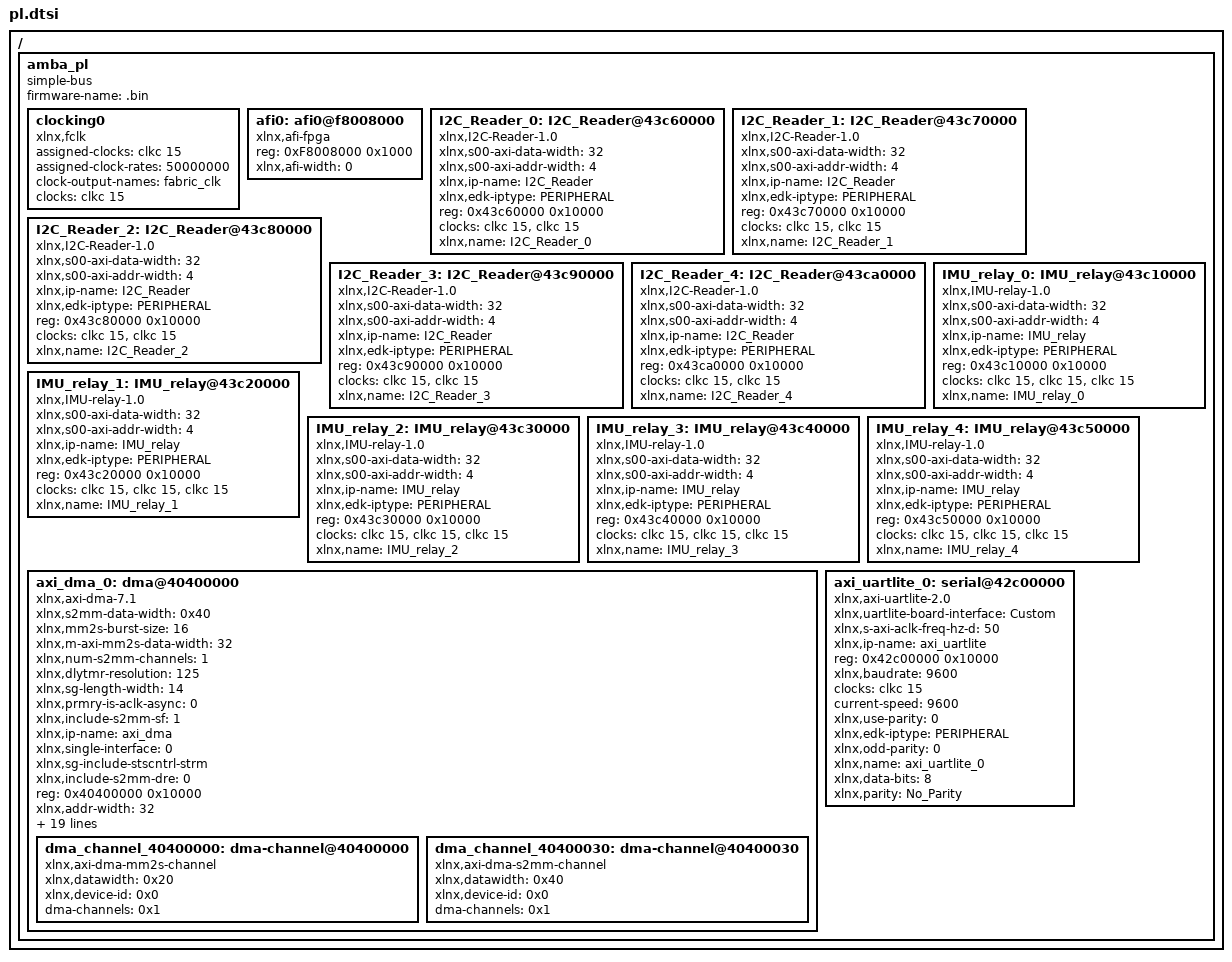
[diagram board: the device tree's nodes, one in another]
/ {
	amba_pl: amba_pl {
		ranges;
		compatible = "simple-bus";
		#address-cells = <1>;
		#size-cells = <1>;
		firmware-name = ".bin";
		clocking0: clocking0 {
			compatible = "xlnx,fclk";
			assigned-clocks = <&clkc 15>;
			assigned-clock-rates = <50000000>;
			#clock-cells = <0>;
			clock-output-names = "fabric_clk";
			clocks = <&clkc 15>;
		};
		afi0: afi0@f8008000 {
			status = "okay";
			compatible = "xlnx,afi-fpga";
			#address-cells = <1>;
			reg = <0xF8008000 0x1000>;
			#size-cells = <0>;
			xlnx,afi-width = <0>;
		};
		I2C_Reader_0: I2C_Reader@43c60000 {
			xlnx,s00-axi-data-width = <32>;
			compatible = "xlnx,I2C-Reader-1.0";
			status = "okay";
			clock-names = "m00_axis_aclk" , "s00_axi_aclk";
			xlnx,s00-axi-addr-width = <4>;
			xlnx,ip-name = "I2C_Reader";
			xlnx,edk-iptype = "PERIPHERAL";
			reg = <0x43c60000 0x10000>;
			clocks = <&clkc 15>, <&clkc 15>;
			xlnx,name = "I2C_Reader_0";
		};
		I2C_Reader_1: I2C_Reader@43c70000 {
			xlnx,s00-axi-data-width = <32>;
			compatible = "xlnx,I2C-Reader-1.0";
			status = "okay";
			clock-names = "m00_axis_aclk" , "s00_axi_aclk";
			xlnx,s00-axi-addr-width = <4>;
			xlnx,ip-name = "I2C_Reader";
			xlnx,edk-iptype = "PERIPHERAL";
			reg = <0x43c70000 0x10000>;
			clocks = <&clkc 15>, <&clkc 15>;
			xlnx,name = "I2C_Reader_1";
		};
		I2C_Reader_2: I2C_Reader@43c80000 {
			xlnx,s00-axi-data-width = <32>;
			compatible = "xlnx,I2C-Reader-1.0";
			status = "okay";
			clock-names = "m00_axis_aclk" , "s00_axi_aclk";
			xlnx,s00-axi-addr-width = <4>;
			xlnx,ip-name = "I2C_Reader";
			xlnx,edk-iptype = "PERIPHERAL";
			reg = <0x43c80000 0x10000>;
			clocks = <&clkc 15>, <&clkc 15>;
			xlnx,name = "I2C_Reader_2";
		};
		I2C_Reader_3: I2C_Reader@43c90000 {
			xlnx,s00-axi-data-width = <32>;
			compatible = "xlnx,I2C-Reader-1.0";
			status = "okay";
			clock-names = "m00_axis_aclk" , "s00_axi_aclk";
			xlnx,s00-axi-addr-width = <4>;
			xlnx,ip-name = "I2C_Reader";
			xlnx,edk-iptype = "PERIPHERAL";
			reg = <0x43c90000 0x10000>;
			clocks = <&clkc 15>, <&clkc 15>;
			xlnx,name = "I2C_Reader_3";
		};
		I2C_Reader_4: I2C_Reader@43ca0000 {
			xlnx,s00-axi-data-width = <32>;
			compatible = "xlnx,I2C-Reader-1.0";
			status = "okay";
			clock-names = "m00_axis_aclk" , "s00_axi_aclk";
			xlnx,s00-axi-addr-width = <4>;
			xlnx,ip-name = "I2C_Reader";
			xlnx,edk-iptype = "PERIPHERAL";
			reg = <0x43ca0000 0x10000>;
			clocks = <&clkc 15>, <&clkc 15>;
			xlnx,name = "I2C_Reader_4";
		};
		IMU_relay_0: IMU_relay@43c10000 {
			xlnx,s00-axi-data-width = <32>;
			compatible = "xlnx,IMU-relay-1.0";
			status = "okay";
			clock-names = "m00_axis_aclk" , "s00_axi_aclk" , "s00_axis_aclk";
			xlnx,s00-axi-addr-width = <4>;
			xlnx,ip-name = "IMU_relay";
			xlnx,edk-iptype = "PERIPHERAL";
			reg = <0x43c10000 0x10000>;
			clocks = <&clkc 15>, <&clkc 15>, <&clkc 15>;
			xlnx,name = "IMU_relay_0";
		};
		IMU_relay_1: IMU_relay@43c20000 {
			xlnx,s00-axi-data-width = <32>;
			compatible = "xlnx,IMU-relay-1.0";
			status = "okay";
			clock-names = "m00_axis_aclk" , "s00_axi_aclk" , "s00_axis_aclk";
			xlnx,s00-axi-addr-width = <4>;
			xlnx,ip-name = "IMU_relay";
			xlnx,edk-iptype = "PERIPHERAL";
			reg = <0x43c20000 0x10000>;
			clocks = <&clkc 15>, <&clkc 15>, <&clkc 15>;
			xlnx,name = "IMU_relay_1";
		};
		IMU_relay_2: IMU_relay@43c30000 {
			xlnx,s00-axi-data-width = <32>;
			compatible = "xlnx,IMU-relay-1.0";
			status = "okay";
			clock-names = "m00_axis_aclk" , "s00_axi_aclk" , "s00_axis_aclk";
			xlnx,s00-axi-addr-width = <4>;
			xlnx,ip-name = "IMU_relay";
			xlnx,edk-iptype = "PERIPHERAL";
			reg = <0x43c30000 0x10000>;
			clocks = <&clkc 15>, <&clkc 15>, <&clkc 15>;
			xlnx,name = "IMU_relay_2";
		};
		IMU_relay_3: IMU_relay@43c40000 {
			xlnx,s00-axi-data-width = <32>;
			compatible = "xlnx,IMU-relay-1.0";
			status = "okay";
			clock-names = "m00_axis_aclk" , "s00_axi_aclk" , "s00_axis_aclk";
			xlnx,s00-axi-addr-width = <4>;
			xlnx,ip-name = "IMU_relay";
			xlnx,edk-iptype = "PERIPHERAL";
			reg = <0x43c40000 0x10000>;
			clocks = <&clkc 15>, <&clkc 15>, <&clkc 15>;
			xlnx,name = "IMU_relay_3";
		};
		IMU_relay_4: IMU_relay@43c50000 {
			xlnx,s00-axi-data-width = <32>;
			compatible = "xlnx,IMU-relay-1.0";
			status = "okay";
			clock-names = "m00_axis_aclk" , "s00_axi_aclk" , "s00_axis_aclk";
			xlnx,s00-axi-addr-width = <4>;
			xlnx,ip-name = "IMU_relay";
			xlnx,edk-iptype = "PERIPHERAL";
			reg = <0x43c50000 0x10000>;
			clocks = <&clkc 15>, <&clkc 15>, <&clkc 15>;
			xlnx,name = "IMU_relay_4";
		};
		axi_dma_0: dma@40400000 {
			compatible = "xlnx,axi-dma-7.1" , "xlnx,axi-dma-1.00.a";
			xlnx,s2mm-data-width = <0x40>;
			xlnx,mm2s-burst-size = <16>;
			xlnx,m-axi-mm2s-data-width = <32>;
			xlnx,num-s2mm-channels = <1>;
			xlnx,dlytmr-resolution = <125>;
			xlnx,sg-length-width = <14>;
			xlnx,prmry-is-aclk-async = <0>;
			xlnx,include-s2mm-sf = <1>;
			#dma-cells = <1>;
			xlnx,ip-name = "axi_dma";
			xlnx,single-interface = <0>;
			xlnx,sg-include-stscntrl-strm;
			xlnx,include-s2mm-dre = <0>;
			reg = <0x40400000 0x10000>;
			xlnx,addr-width = <32>;
			xlnx,include-s2mm = <1>;
			clocks = <&clkc 15>, <&clkc 15>, <&clkc 15>, <&clkc 15>;
			xlnx,s-axis-s2mm-tdata-width = <64>;
			xlnx,micro-dma = <0>;
			xlnx,increase-throughput = <0>;
			xlnx,mm2s-data-width = <0x20>;
			xlnx,addrwidth = <0x20>;
			xlnx,include-sg;
			xlnx,sg-use-stsapp-length = <0>;
			xlnx,m-axis-mm2s-tdata-width = <32>;
			xlnx,edk-iptype = "PERIPHERAL";
			xlnx,s2mm-burst-size = <16>;
			xlnx,m-axi-s2mm-data-width = <64>;
			xlnx,num-mm2s-channels = <1>;
			xlnx,enable-multi-channel = <0>;
			status = "okay";
			xlnx,include-mm2s-sf = <1>;
			clock-names = "m_axi_mm2s_aclk" , "m_axi_s2mm_aclk" , "m_axi_sg_aclk" , "s_axi_lite_aclk";
			xlnx,include-mm2s = <1>;
			xlnx,include-mm2s-dre = <0>;
			xlnx,name = "axi_dma_0";
			dma_channel_40400000: dma-channel@40400000 {
				xlnx,datawidth = <0x20>;
				xlnx,device-id = <0x0>;
				compatible = "xlnx,axi-dma-mm2s-channel";
				dma-channels = <0x1>;
			};
			dma_channel_40400030: dma-channel@40400030 {
				xlnx,datawidth = <0x40>;
				xlnx,device-id = <0x0>;
				compatible = "xlnx,axi-dma-s2mm-channel";
				dma-channels = <0x1>;
			};
		};
		axi_uartlite_0: serial@42c00000 {
			compatible = "xlnx,axi-uartlite-2.0" , "xlnx,xps-uartlite-1.00.a";
			xlnx,uartlite-board-interface = "Custom";
			xlnx,s-axi-aclk-freq-hz-d = <50>;
			xlnx,ip-name = "axi_uartlite";
			reg = <0x42c00000 0x10000>;
			xlnx,baudrate = <9600>;
			clocks = <&clkc 15>;
			current-speed = <9600>;
			xlnx,use-parity = <0>;
			xlnx,edk-iptype = "PERIPHERAL";
			xlnx,odd-parity = <0>;
			status = "okay";
			clock-names = "s_axi_aclk";
			xlnx,name = "axi_uartlite_0";
			xlnx,data-bits = <8>;
			xlnx,parity = "No_Parity";
		};
	};
};
